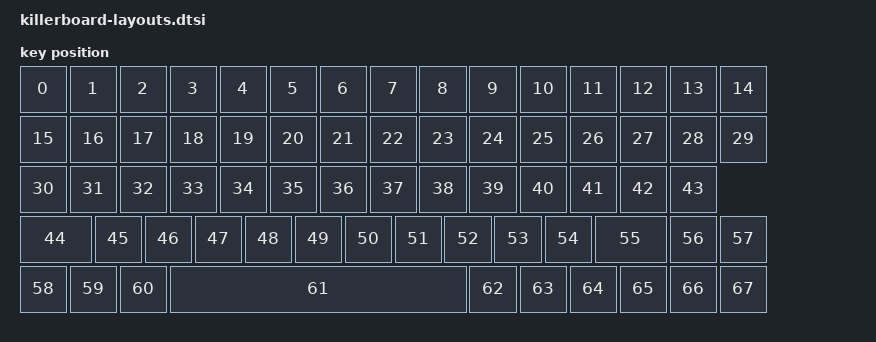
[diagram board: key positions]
#include <physical_layouts.dtsi>

/ {
    physical_layout0: physical_layout_0 {
        compatible = "zmk,physical-layout";
        display-name = "Default";

        keys =
        // Row 1
          <&key_physical_attrs 100 100    0    0 0 0 0>   // ESC
        , <&key_physical_attrs 100 100  100    0 0 0 0>
        , <&key_physical_attrs 100 100  200    0 0 0 0>
        , <&key_physical_attrs 100 100  300    0 0 0 0>
        , <&key_physical_attrs 100 100  400    0 0 0 0>
        , <&key_physical_attrs 100 100  500    0 0 0 0>
        , <&key_physical_attrs 100 100  600    0 0 0 0>
        , <&key_physical_attrs 100 100  700    0 0 0 0>
        , <&key_physical_attrs 100 100  800    0 0 0 0>
        , <&key_physical_attrs 100 100  900    0 0 0 0>
        , <&key_physical_attrs 100 100 1000    0 0 0 0>
        , <&key_physical_attrs 100 100 1100    0 0 0 0>
        , <&key_physical_attrs 100 100 1200    0 0 0 0>
        , <&key_physical_attrs 100 100 1300    0 0 0 0>
        , <&key_physical_attrs 100 100 1400    0 0 0 0>

        // Row 2
        , <&key_physical_attrs 100 100    0  100 0 0 0>   // TAB
        , <&key_physical_attrs 100 100  100  100 0 0 0>
        , <&key_physical_attrs 100 100  200  100 0 0 0>
        , <&key_physical_attrs 100 100  300  100 0 0 0>
        , <&key_physical_attrs 100 100  400  100 0 0 0>
        , <&key_physical_attrs 100 100  500  100 0 0 0>
        , <&key_physical_attrs 100 100  600  100 0 0 0>
        , <&key_physical_attrs 100 100  700  100 0 0 0>
        , <&key_physical_attrs 100 100  800  100 0 0 0>
        , <&key_physical_attrs 100 100  900  100 0 0 0>
        , <&key_physical_attrs 100 100 1000  100 0 0 0>
        , <&key_physical_attrs 100 100 1100  100 0 0 0>
        , <&key_physical_attrs 100 100 1200  100 0 0 0>
        , <&key_physical_attrs 100 100 1300  100 0 0 0>
        , <&key_physical_attrs 100 100 1400  100 0 0 0>

        // Row 3
        , <&key_physical_attrs 100 100    0  200 0 0 0>   // CAPS
        , <&key_physical_attrs 100 100  100  200 0 0 0>
        , <&key_physical_attrs 100 100  200  200 0 0 0>
        , <&key_physical_attrs 100 100  300  200 0 0 0>
        , <&key_physical_attrs 100 100  400  200 0 0 0>
        , <&key_physical_attrs 100 100  500  200 0 0 0>
        , <&key_physical_attrs 100 100  600  200 0 0 0>
        , <&key_physical_attrs 100 100  700  200 0 0 0>
        , <&key_physical_attrs 100 100  800  200 0 0 0>
        , <&key_physical_attrs 100 100  900  200 0 0 0>
        , <&key_physical_attrs 100 100 1000  200 0 0 0>
        , <&key_physical_attrs 100 100 1100  200 0 0 0>
        , <&key_physical_attrs 100 100 1200  200 0 0 0>
        , <&key_physical_attrs 100 100 1300  200 0 0 0>

        // Row 4
        , <&key_physical_attrs 150 100    0  300 0 0 0>   // LSHIFT (1.5U)
        , <&key_physical_attrs 100 100  150  300 0 0 0>
        , <&key_physical_attrs 100 100  250  300 0 0 0>
        , <&key_physical_attrs 100 100  350  300 0 0 0>
        , <&key_physical_attrs 100 100  450  300 0 0 0>
        , <&key_physical_attrs 100 100  550  300 0 0 0>
        , <&key_physical_attrs 100 100  650  300 0 0 0>
        , <&key_physical_attrs 100 100  750  300 0 0 0>
        , <&key_physical_attrs 100 100  850  300 0 0 0>
        , <&key_physical_attrs 100 100  950  300 0 0 0>
        , <&key_physical_attrs 100 100 1050  300 0 0 0>
        , <&key_physical_attrs 150 100 1150  300 0 0 0>   // RSHIFT (1.5U)
        , <&key_physical_attrs 100 100 1300  300 0 0 0>
        , <&key_physical_attrs 100 100 1400  300 0 0 0>

        // Row 5
        , <&key_physical_attrs 100 100    0  400 0 0 0>   // CTRL
        , <&key_physical_attrs 100 100  100  400 0 0 0>
        , <&key_physical_attrs 100 100  200  400 0 0 0>
        , <&key_physical_attrs 600 100  300  400 0 0 0>   // Space (6U)
        , <&key_physical_attrs 100 100  900  400 0 0 0>
        , <&key_physical_attrs 100 100 1000  400 0 0 0>
        , <&key_physical_attrs 100 100 1100  400 0 0 0>
        , <&key_physical_attrs 100 100 1200  400 0 0 0>
        , <&key_physical_attrs 100 100 1300  400 0 0 0>
        , <&key_physical_attrs 100 100 1400  400 0 0 0>
        ;
    };
};

